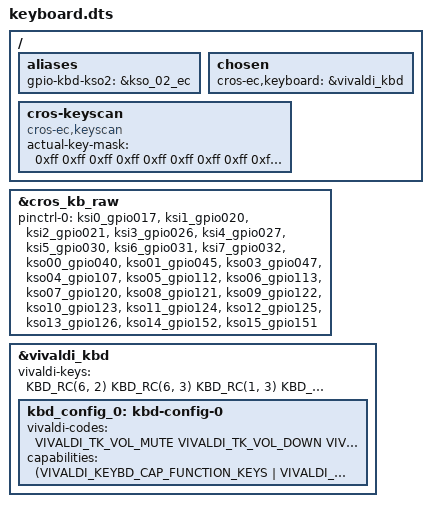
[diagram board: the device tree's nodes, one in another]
/* Copyright 2022 The ChromiumOS Authors
 * Use of this source code is governed by a BSD-style license that can be
 * found in the LICENSE file.
 */

&cros_kb_raw {
	status = "okay";
	pinctrl-0 = <
		&ksi0_gpio017
		&ksi1_gpio020
		&ksi2_gpio021
		&ksi3_gpio026
		&ksi4_gpio027
		&ksi5_gpio030
		&ksi6_gpio031
		&ksi7_gpio032
		&kso00_gpio040
		&kso01_gpio045
		/* No KSO2 (it's inverted and implemented by GPIO) &kso02_gpio046 */
		&kso03_gpio047
		&kso04_gpio107
		&kso05_gpio112
		&kso06_gpio113
		&kso07_gpio120
		&kso08_gpio121
		&kso09_gpio122
		&kso10_gpio123
		&kso11_gpio124
		&kso12_gpio125
		&kso13_gpio126
		&kso14_gpio152
		&kso15_gpio151
	>;
	pinctrl-names = "default";
};

/ {
	aliases {
		gpio-kbd-kso2 = &kso_02_ec;
	};

	chosen {
		//cros-ec,keyboard = &kdb;
		cros-ec,keyboard = &vivaldi_kbd;
	};

	cros-keyscan {
		compatible = "cros-ec,keyscan";

		/* TODO: Use actual values */
		actual-key-mask = <
			0xff  /* C0 */
			0xff  /* C1 */
			0xff  /* C2 */
			0xff  /* C3 */
			0xff  /* C4 */
			0xff  /* C5 */
			0xff  /* C6 */
			0xff  /* C7 */
			0xff  /* C8 */
			0xff  /* C9 */
			0xff  /* C10 */
			0xff  /* C11 */
			0xff  /* C12 */
			0xff  /* C13 */
			0xff  /* C14 */
			0xff  /* C15 */
			>;
	};
};

&vivaldi_kbd {
	vivaldi-keys = <
		KBD_RC(6, 2)   /* T1 */
		KBD_RC(6, 3)   /* T2 */
		KBD_RC(1, 3)   /* T3 */
		KBD_RC(3, 3)   /* T4 */
		KBD_RC(7, 0)   /* T5 */
		KBD_RC(3, 6)   /* T6 */
		KBD_RC(1, 7)   /* T7 */
		KBD_RC(6, 7)   /* T8 */
		KBD_RC(6, 10)  /* T9 */
		KBD_RC(7, 10)  /* T10 */
		KBD_RC(3, 10)  /* T11 */
		KBD_RC(5, 10)  /* T12 */
	>;

	kbd_config_0: kbd-config-0 {
		vivaldi-codes = <
			VIVALDI_TK_VOL_MUTE           /* T1 */
			VIVALDI_TK_VOL_DOWN           /* T2 */
			VIVALDI_TK_VOL_UP             /* T3 */
			VIVALDI_TK_PLAY_PAUSE         /* T4 */
			VIVALDI_TK_FULLSCREEN         /* T5* */
			VIVALDI_TK_SNAPSHOT           /* T6* */
			VIVALDI_TK_BACK               /* T7* */
			VIVALDI_TK_REFRESH            /* T8* */
			VIVALDI_TK_BRIGHTNESS_DOWN    /* T9 */
			VIVALDI_TK_BRIGHTNESS_UP      /* T10 */
			VIVALDI_TK_DONOTDISTURB       /* T11* */
			VIVALDI_TK_OVERVIEW           /* T12* */
		>;
		capabilities = <(VIVALDI_KEYBD_CAP_FUNCTION_KEYS |
				VIVALDI_KEYBD_CAP_SCRNLOCK_KEY |
				VIVALDI_KEYBD_CAP_ASSISTANT_KEY)>;
	};
};

/*
&kbd {
        kso-gpio {
		compatible = "cros-ec,col-gpio";
		col-num = <2>;
		col-gpios = <&gpio1 7 GPIO_ACTIVE_HIGH>;
	};
};
*/
